# PIC32CX1012BZ25032 register map
Vendor: Microchip Technology; Series: BZ25; File version: 0
CPU: CM4 r0p1, little endian, MPU, FPU, 3 interrupt priority bits
Registers are 32-bit, read-write, reset 0x0 unless marked. A register's access mark holds for its fields unless they carry their own. Offsets are from the block's base; [hi:lo] are bit positions; {n}, {i} and the like mark numbered series; 'fields as' and 'values as' point back to an identical list.

## BLE
Base 0x41012000; register names take the prefix BLE_
0x4B8 DPLL_RG1 16-bit
  [15:0] DPLL_RG1BITS
0x4BA DPLL_RG2 16-bit
  [15:0] DPLL_RG2BITS

## BTZBSYS — BT ZB Subsystem
Base 0x41014000; register names take the prefix BTZBSYS_
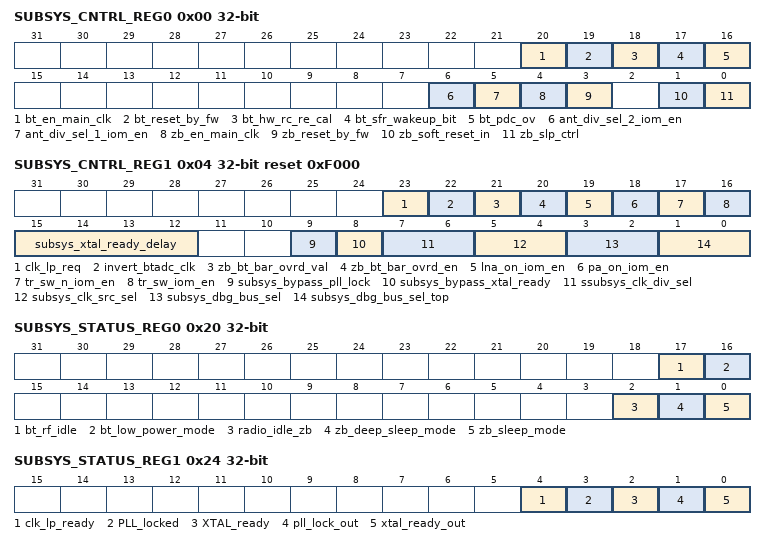
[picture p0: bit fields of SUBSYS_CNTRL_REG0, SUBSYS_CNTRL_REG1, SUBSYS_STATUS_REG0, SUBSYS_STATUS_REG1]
0x00 SUBSYS_CNTRL_REG0
  [20] bt_en_main_clk, [19] bt_reset_by_fw, [18] bt_hw_rc_re_cal, [17] bt_sfr_wakeup_bit, [16] bt_pdc_ov, [6] ant_div_sel_2_iom_en, [5] ant_div_sel_1_iom_en, [4] zb_en_main_clk, [3] zb_reset_by_fw, [1] zb_soft_reset_in, [0] zb_slp_ctrl
0x04 SUBSYS_CNTRL_REG1 reset 0xF000
  [23] clk_lp_req
  [22] invert_btadc_clk
  [21] zb_bt_bar_ovrd_val
  [20] zb_bt_bar_ovrd_en
  [19] lna_on_iom_en
  [18] pa_on_iom_en
  [17] tr_sw_n_iom_en
  [16] tr_sw_iom_en
  [15:12] subsys_xtal_ready_delay
  [9] subsys_bypass_pll_lock
  [8] subsys_bypass_xtal_ready
  [7:6] ssubsys_clk_div_sel — subsys_clk_div_sel
  [5:4] subsys_clk_src_sel
  [3:2] subsys_dbg_bus_sel
  [1:0] subsys_dbg_bus_sel_top
0x20 SUBSYS_STATUS_REG0
  [17] bt_rf_idle, [16] bt_low_power_mode, [2] radio_idle_zb, [1] zb_deep_sleep_mode, [0] zb_sleep_mode
0x24 SUBSYS_STATUS_REG1
  [4] clk_lp_ready, [3] PLL_locked, [2] XTAL_ready, [1] pll_lock_out, [0] xtal_ready_out

## CCL — Configurable Custom Logic
Base 0x42001800; register names take the prefix CCL_
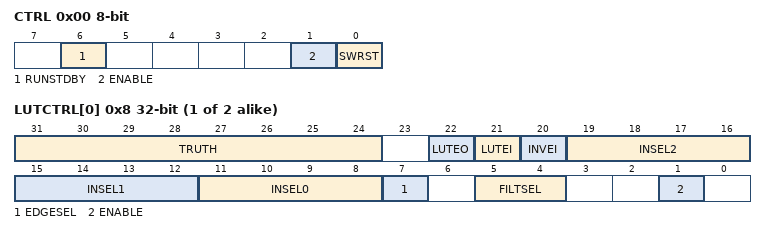
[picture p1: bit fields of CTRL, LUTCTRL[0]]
0x00 CTRL 8-bit — Control
  [6] RUNSTDBY — Run in Standby
    0=DISABLE (Generic clock is not required in standby sleep mode); 1=ENABLE (Generic clock is required in standby sleep mode)
  [1] ENABLE
    0=DISABLE (The peripheral is disabled); 1=ENABLE (The peripheral is enabled)
  [0] SWRST — Software Reset
    0=DISABLE (The peripheral is not reset); 1=ENABLE (The peripheral is reset)
{0x4+i} SEQCTRL[{i}] (i=0..1) 8-bit — SEQ Control x
  [3:0] SEQSEL — Sequential Selection
    0=DISABLE (Sequential logic is disabled); 1=DFF (D flip flop); 2=JK (JK flip flop); 3=LATCH (D latch); 4=RS (RS latch)
{0x8+4i} LUTCTRL[{i}] (i=0..1) — LUT Control x
  [31:24] TRUTH — Truth Value
  [22] LUTEO — LUT Event Output Enable
    0=DISABLE (LUT event output is disabled); 1=ENABLE (LUT event output is enabled)
  [21] LUTEI — LUT Event Input Enable
    0=DISABLE (LUT incoming event is disabled); 1=ENABLE (LUT incoming event is enabled)
  [20] INVEI — Inverted Event Input Enable
    0=DISABLE (Incoming event is not inverted); 1=ENABLE (Incoming event is inverted)
  [19:16] INSEL2 — Input Selection 2
    0=MASK (Masked input); 1=FEEDBACK (Feedback input source); 2=LINK (Linked LUT input source); 3=EVENT (Event input source); 4=IO (I/O pin input source); 5=AC (AC input source); 6=TC (TC input source); 7=ALTTC (Alternate TC input source); 8=TCC (TCC input source); 9=SERCOM (SERCOM input source)
  [15:12] INSEL1 — Input Selection 1
    values as INSEL2
  [11:8] INSEL0 — Input Selection 0
    values as INSEL2
  [7] EDGESEL — Edge Selection
    0=DISABLE (Edge detector is disabled); 1=ENABLE (Edge detector is enabled)
  [5:4] FILTSEL — Filter Selection
    0=DISABLE (Filter disabled); 1=SYNCH (Synchronizer enabled); 2=FILTER (Filter enabled)
  [1] ENABLE — LUT Enable
    0=DISABLE (LUT block is disabled); 1=ENABLE (LUT block is enabled)

## CMCC — Cortex M Cache Controller
Base 0x41002000; register names take the prefix CMCC_
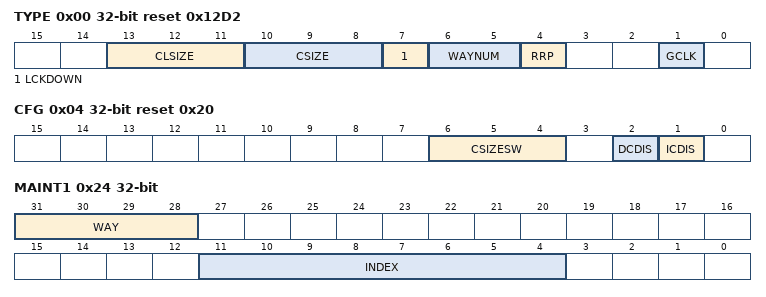
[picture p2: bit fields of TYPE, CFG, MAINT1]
0x00 TYPE ro reset 0x12D2 — Cache Type Register
  [13:11] CLSIZE — Cache Line Size
    0=CLSIZE_4B (Cache Line Size is 4 bytes); 1=CLSIZE_8B (Cache Line Size is 8 bytes); 2=CLSIZE_16B (Cache Line Size is 16 bytes); 3=CLSIZE_32B (Cache Line Size is 32 bytes); 4=CLSIZE_64B (Cache Line Size is 64 bytes); 5=CLSIZE_128B (Cache Line Size is 128 bytes)
  [10:8] CSIZE — Cache Size
    0=CSIZE_1KB (Cache Size is 1 KB); 1=CSIZE_2KB (Cache Size is 2 KB); 2=CSIZE_4KB (Cache Size is 4 KB); 3=CSIZE_8KB (Cache Size is 8 KB); 4=CSIZE_16KB (Cache Size is 16 KB); 5=CSIZE_32KB (Cache Size is 32 KB); 6=CSIZE_64KB (Cache Size is 64 KB)
  [7] LCKDOWN — Lock Down supported
  [6:5] WAYNUM — Number of Way
    0=DMAPPED (Direct Mapped Cache); 1=ARCH2WAY (2-WAY set associative); 2=ARCH4WAY (4-WAY set associative)
  [4] RRP — Round Robin Policy supported
  [1] GCLK — dynamic Clock Gating supported
0x04 CFG reset 0x20 — Cache Configuration Register
  [6:4] CSIZESW — Cache size configured by software
    0=CONF_CSIZE_1KB (The Cache Size is configured to 1KB); 1=CONF_CSIZE_2KB (The Cache Size is configured to 2KB); 2=CONF_CSIZE_4KB (The Cache Size is configured to 4KB); 3=CONF_CSIZE_8KB (The Cache Size is configured to 8KB); 4=CONF_CSIZE_16KB (The Cache Size is configured to 16KB); 5=CONF_CSIZE_32KB (The Cache Size is configured to 32KB); 6=CONF_CSIZE_64KB (The Cache Size is configured to 64KB)
  [2] DCDIS — Data Cache Disable
  [1] ICDIS — Instruction Cache Disable
0x08 CTRL wo — Cache Control Register
  [0] CEN — Cache Controller Enable
0x0C SR ro — Cache Status Register
  [0] CSTS — Cache Controller Status
0x10 LCKWAY — Cache Lock per Way Register
  [3:0] LCKWAY — Lockdown way Register
0x20 MAINT0 wo — Cache Maintenance Register 0
  [0] INVALL — Cache Controller invalidate All
0x24 MAINT1 wo — Cache Maintenance Register 1
  [31:28] WAY — Invalidate Way
    {v}=Way {v} is selection for index invalidation (v=0..3)
  [11:4] INDEX — Invalidate Index
0x28 MCFG — Cache Monitor Configuration Register
  [1:0] MODE — Cache Controller Monitor Counter Mode
    0=CYCLE_COUNT (Cycle counter); 1=IHIT_COUNT (Instruction hit counter); 2=DHIT_COUNT (Data hit counter)
0x2C MEN — Cache Monitor Enable Register
  [0] MENABLE — Cache Controller Monitor Enable
0x30 MCTRL wo — Cache Monitor Control Register
  [0] SWRST — Cache Controller Software Reset
0x34 MSR ro — Cache Monitor Status Register
  [31:0] EVENT_CNT — Monitor Event Counter

## Notices in the file
Copyright (c) 2017 Microchip Technology Inc.
SPDX-License-Identifier: Apache-2.0
Licensed under the Apache License, Version 2.0 (the "License");
you may not use this file except in compliance with the License.
You may obtain a copy of the License at
http://www.apache.org/licenses/LICENSE-2.0
Unless required by applicable law or agreed to in writing, software
distributed under the License is distributed on an "AS IS" BASIS,
WITHOUT WARRANTIES OR CONDITIONS OF ANY KIND, either express or implied.
See the License for the specific language governing permissions and
limitations under the License.
